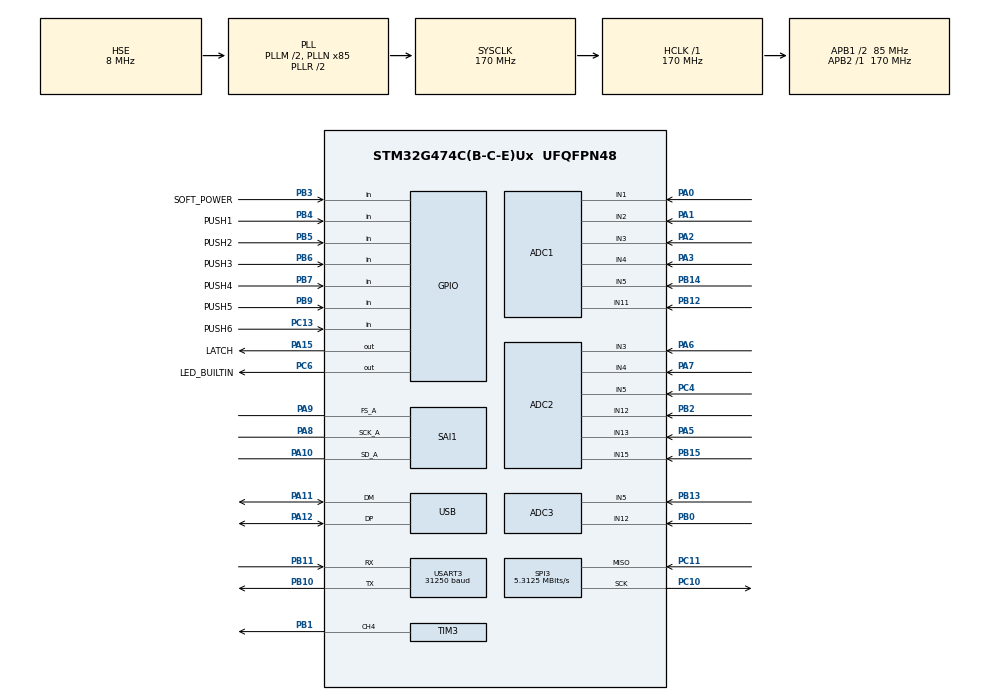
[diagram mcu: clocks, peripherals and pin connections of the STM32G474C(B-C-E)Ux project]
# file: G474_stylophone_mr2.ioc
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ADC1.Channel-0\#ChannelRegularConversion=ADC_CHANNEL_1
ADC1.Channel-1\#ChannelRegularConversion=ADC_CHANNEL_2
ADC1.Channel-2\#ChannelRegularConversion=ADC_CHANNEL_3
ADC1.Channel-3\#ChannelRegularConversion=ADC_CHANNEL_4
ADC1.Channel-4\#ChannelRegularConversion=ADC_CHANNEL_5
ADC1.Channel-5\#ChannelRegularConversion=ADC_CHANNEL_11
ADC1.DMAContinuousRequests=ENABLE
ADC1.EOCSelection=ADC_EOC_SEQ_CONV
ADC1.ExternalTrigConv=ADC_EXTERNALTRIG_T15_TRGO
ADC1.NbrOfConversion=6
ADC1.NbrOfConversionFlag=1
ADC1.OffsetNumber-0\#ChannelRegularConversion=ADC_OFFSET_NONE
ADC1.OffsetNumber-1\#ChannelRegularConversion=ADC_OFFSET_NONE
ADC1.OffsetNumber-2\#ChannelRegularConversion=ADC_OFFSET_NONE
ADC1.OffsetNumber-3\#ChannelRegularConversion=ADC_OFFSET_NONE
ADC1.OffsetNumber-4\#ChannelRegularConversion=ADC_OFFSET_NONE
ADC1.OffsetNumber-5\#ChannelRegularConversion=ADC_OFFSET_NONE
ADC1.Rank-0\#ChannelRegularConversion=1
ADC1.Rank-1\#ChannelRegularConversion=2
ADC1.Rank-2\#ChannelRegularConversion=3
ADC1.Rank-3\#ChannelRegularConversion=4
ADC1.Rank-4\#ChannelRegularConversion=5
ADC1.Rank-5\#ChannelRegularConversion=6
ADC1.SamplingTime-0\#ChannelRegularConversion=ADC_SAMPLETIME_2CYCLES_5
ADC1.SamplingTime-1\#ChannelRegularConversion=ADC_SAMPLETIME_2CYCLES_5
ADC1.SamplingTime-2\#ChannelRegularConversion=ADC_SAMPLETIME_2CYCLES_5
ADC1.SamplingTime-3\#ChannelRegularConversion=ADC_SAMPLETIME_2CYCLES_5
ADC1.SamplingTime-4\#ChannelRegularConversion=ADC_SAMPLETIME_2CYCLES_5
ADC1.SamplingTime-5\#ChannelRegularConversion=ADC_SAMPLETIME_2CYCLES_5
ADC1.master=1
ADC2.Channel-0\#ChannelRegularConversion=ADC_CHANNEL_3
ADC2.Channel-1\#ChannelRegularConversion=ADC_CHANNEL_4
ADC2.Channel-2\#ChannelRegularConversion=ADC_CHANNEL_5
ADC2.Channel-3\#ChannelRegularConversion=ADC_CHANNEL_12
ADC2.Channel-4\#ChannelRegularConversion=ADC_CHANNEL_13
ADC2.Channel-5\#ChannelRegularConversion=ADC_CHANNEL_15
ADC2.DMAContinuousRequests=ENABLE
ADC2.EOCSelection=ADC_EOC_SEQ_CONV
ADC2.ExternalTrigConv=ADC_EXTERNALTRIG_T15_TRGO
ADC2.NbrOfConversion=6
ADC2.NbrOfConversionFlag=1
ADC2.OffsetNumber-0\#ChannelRegularConversion=ADC_OFFSET_NONE
ADC2.OffsetNumber-1\#ChannelRegularConversion=ADC_OFFSET_NONE
ADC2.OffsetNumber-2\#ChannelRegularConversion=ADC_OFFSET_NONE
ADC2.OffsetNumber-3\#ChannelRegularConversion=ADC_OFFSET_NONE
ADC2.OffsetNumber-4\#ChannelRegularConversion=ADC_OFFSET_NONE
ADC2.OffsetNumber-5\#ChannelRegularConversion=ADC_OFFSET_NONE
ADC2.Rank-0\#ChannelRegularConversion=1
ADC2.Rank-1\#ChannelRegularConversion=2
ADC2.Rank-2\#ChannelRegularConversion=3
ADC2.Rank-3\#ChannelRegularConversion=4
ADC2.Rank-4\#ChannelRegularConversion=5
ADC2.Rank-5\#ChannelRegularConversion=6
ADC2.SamplingTime-0\#ChannelRegularConversion=ADC_SAMPLETIME_2CYCLES_5
ADC2.SamplingTime-1\#ChannelRegularConversion=ADC_SAMPLETIME_2CYCLES_5
ADC2.SamplingTime-2\#ChannelRegularConversion=ADC_SAMPLETIME_2CYCLES_5
ADC2.SamplingTime-3\#ChannelRegularConversion=ADC_SAMPLETIME_2CYCLES_5
ADC2.SamplingTime-4\#ChannelRegularConversion=ADC_SAMPLETIME_2CYCLES_5
ADC2.SamplingTime-5\#ChannelRegularConversion=ADC_SAMPLETIME_2CYCLES_5
ADC3.Channel-0\#ChannelRegularConversion=ADC_CHANNEL_5
ADC3.Channel-1\#ChannelRegularConversion=ADC_CHANNEL_12
ADC3.DMAContinuousRequests=ENABLE
ADC3.EOCSelection=ADC_EOC_SEQ_CONV
ADC3.ExternalTrigConv=ADC_EXTERNALTRIG_T15_TRGO
ADC3.NbrOfConversion=2
ADC3.NbrOfConversionFlag=1
ADC3.OffsetNumber-0\#ChannelRegularConversion=ADC_OFFSET_NONE
ADC3.OffsetNumber-1\#ChannelRegularConversion=ADC_OFFSET_NONE
ADC3.OversamplingMode=DISABLE
ADC3.Rank-0\#ChannelRegularConversion=1
ADC3.Rank-1\#ChannelRegularConversion=2
ADC3.SamplingTime-0\#ChannelRegularConversion=ADC_SAMPLETIME_2CYCLES_5
ADC3.SamplingTime-1\#ChannelRegularConversion=ADC_SAMPLETIME_2CYCLES_5
ADC3.master=1
Dma.ADC1.0.Direction=DMA_PERIPH_TO_MEMORY
Dma.ADC1.0.EventEnable=DISABLE
Dma.ADC1.0.Instance=DMA1_Channel1
Dma.ADC1.0.MemDataAlignment=DMA_MDATAALIGN_WORD
Dma.ADC1.0.MemInc=DMA_MINC_ENABLE
Dma.ADC1.0.Mode=DMA_CIRCULAR
Dma.ADC1.0.PeriphDataAlignment=DMA_PDATAALIGN_WORD
Dma.ADC1.0.PeriphInc=DMA_PINC_DISABLE
Dma.ADC1.0.Polarity=HAL_DMAMUX_REQ_GEN_RISING
Dma.ADC1.0.Priority=DMA_PRIORITY_LOW
Dma.ADC1.0.RequestNumber=1
Dma.ADC1.0.SignalID=NONE
Dma.ADC1.0.SyncEnable=DISABLE
Dma.ADC1.0.SyncPolarity=HAL_DMAMUX_SYNC_NO_EVENT
Dma.ADC1.0.SyncRequestNumber=1
Dma.ADC1.0.SyncSignalID=NONE
Dma.ADC2.1.Direction=DMA_PERIPH_TO_MEMORY
Dma.ADC2.1.EventEnable=DISABLE
Dma.ADC2.1.Instance=DMA1_Channel2
Dma.ADC2.1.MemDataAlignment=DMA_MDATAALIGN_WORD
Dma.ADC2.1.MemInc=DMA_MINC_ENABLE
Dma.ADC2.1.Mode=DMA_CIRCULAR
Dma.ADC2.1.PeriphDataAlignment=DMA_PDATAALIGN_WORD
Dma.ADC2.1.PeriphInc=DMA_PINC_DISABLE
Dma.ADC2.1.Polarity=HAL_DMAMUX_REQ_GEN_RISING
Dma.ADC2.1.Priority=DMA_PRIORITY_LOW
Dma.ADC2.1.RequestNumber=1
Dma.ADC2.1.SignalID=NONE
Dma.ADC2.1.SyncEnable=DISABLE
Dma.ADC2.1.SyncPolarity=HAL_DMAMUX_SYNC_NO_EVENT
Dma.ADC2.1.SyncRequestNumber=1
Dma.ADC2.1.SyncSignalID=NONE
Dma.ADC3.2.Direction=DMA_PERIPH_TO_MEMORY
Dma.ADC3.2.EventEnable=DISABLE
Dma.ADC3.2.Instance=DMA1_Channel3
Dma.ADC3.2.MemDataAlignment=DMA_MDATAALIGN_WORD
Dma.ADC3.2.MemInc=DMA_MINC_ENABLE
Dma.ADC3.2.Mode=DMA_CIRCULAR
Dma.ADC3.2.PeriphDataAlignment=DMA_PDATAALIGN_WORD
Dma.ADC3.2.PeriphInc=DMA_PINC_DISABLE
Dma.ADC3.2.Polarity=HAL_DMAMUX_REQ_GEN_RISING
Dma.ADC3.2.Priority=DMA_PRIORITY_LOW
Dma.ADC3.2.RequestNumber=1
Dma.ADC3.2.SignalID=NONE
Dma.ADC3.2.SyncEnable=DISABLE
Dma.ADC3.2.SyncPolarity=HAL_DMAMUX_SYNC_NO_EVENT
Dma.ADC3.2.SyncRequestNumber=1
Dma.ADC3.2.SyncSignalID=NONE
Dma.Request0=ADC1
Dma.Request1=ADC2
Dma.Request2=ADC3
Dma.Request3=SAI1_A
Dma.Request4=SPI3_RX
Dma.Request5=TIM3_CH4
Dma.SAI1_A.3.Direction=DMA_MEMORY_TO_PERIPH
Dma.SAI1_A.3.EventEnable=DISABLE
Dma.SAI1_A.3.Instance=DMA1_Channel4
Dma.SAI1_A.3.MemDataAlignment=DMA_MDATAALIGN_WORD
Dma.SAI1_A.3.MemInc=DMA_MINC_ENABLE
Dma.SAI1_A.3.Mode=DMA_CIRCULAR
Dma.SAI1_A.3.PeriphDataAlignment=DMA_PDATAALIGN_WORD
Dma.SAI1_A.3.PeriphInc=DMA_PINC_DISABLE
Dma.SAI1_A.3.Polarity=HAL_DMAMUX_REQ_GEN_RISING
Dma.SAI1_A.3.Priority=DMA_PRIORITY_HIGH
Dma.SAI1_A.3.RequestNumber=1
Dma.SAI1_A.3.SignalID=NONE
Dma.SAI1_A.3.SyncEnable=DISABLE
Dma.SAI1_A.3.SyncPolarity=HAL_DMAMUX_SYNC_NO_EVENT
Dma.SAI1_A.3.SyncRequestNumber=1
Dma.SAI1_A.3.SyncSignalID=NONE
Dma.SPI3_RX.4.Direction=DMA_PERIPH_TO_MEMORY
Dma.SPI3_RX.4.EventEnable=DISABLE
Dma.SPI3_RX.4.Instance=DMA1_Channel5
Dma.SPI3_RX.4.MemDataAlignment=DMA_MDATAALIGN_BYTE
Dma.SPI3_RX.4.MemInc=DMA_MINC_ENABLE
Dma.SPI3_RX.4.Mode=DMA_NORMAL
Dma.SPI3_RX.4.PeriphDataAlignment=DMA_PDATAALIGN_BYTE
Dma.SPI3_RX.4.PeriphInc=DMA_PINC_DISABLE
Dma.SPI3_RX.4.Polarity=HAL_DMAMUX_REQ_GEN_RISING
Dma.SPI3_RX.4.Priority=DMA_PRIORITY_LOW
Dma.SPI3_RX.4.RequestNumber=1
Dma.SPI3_RX.4.SignalID=NONE
Dma.SPI3_RX.4.SyncEnable=DISABLE
Dma.SPI3_RX.4.SyncPolarity=HAL_DMAMUX_SYNC_NO_EVENT
Dma.SPI3_RX.4.SyncRequestNumber=1
Dma.SPI3_RX.4.SyncSignalID=NONE
Dma.TIM3_CH4.5.Direction=DMA_MEMORY_TO_PERIPH
Dma.TIM3_CH4.5.EventEnable=DISABLE
Dma.TIM3_CH4.5.Instance=DMA1_Channel6
Dma.TIM3_CH4.5.MemDataAlignment=DMA_MDATAALIGN_BYTE
Dma.TIM3_CH4.5.MemInc=DMA_MINC_ENABLE
Dma.TIM3_CH4.5.Mode=DMA_NORMAL
Dma.TIM3_CH4.5.PeriphDataAlignment=DMA_PDATAALIGN_WORD
Dma.TIM3_CH4.5.PeriphInc=DMA_PINC_DISABLE
Dma.TIM3_CH4.5.Polarity=HAL_DMAMUX_REQ_GEN_RISING
Dma.TIM3_CH4.5.Priority=DMA_PRIORITY_LOW
Dma.TIM3_CH4.5.RequestNumber=1
Dma.TIM3_CH4.5.SignalID=NONE
Dma.TIM3_CH4.5.SyncEnable=DISABLE
Dma.TIM3_CH4.5.SyncPolarity=HAL_DMAMUX_SYNC_NO_EVENT
Dma.TIM3_CH4.5.SyncRequestNumber=1
Dma.TIM3_CH4.5.SyncSignalID=NONE
Mcu.Family=STM32G4
Mcu.Name=STM32G474C(B-C-E)Ux
Mcu.Package=UFQFPN48
NVIC.DMA1_Channel1_IRQn=true\:0\:0\:false\:false\:true\:false\:true\:true
NVIC.DMA1_Channel2_IRQn=true\:0\:0\:false\:false\:true\:false\:true\:true
NVIC.DMA1_Channel3_IRQn=true\:0\:0\:false\:false\:true\:false\:true\:true
NVIC.DMA1_Channel4_IRQn=true\:10\:0\:true\:false\:true\:false\:true\:true
NVIC.DMA1_Channel5_IRQn=true\:0\:0\:false\:false\:true\:false\:true\:true
NVIC.DMA1_Channel6_IRQn=true\:0\:0\:false\:false\:true\:false\:true\:true
NVIC.PriorityGroup=NVIC_PRIORITYGROUP_4
NVIC.USB_LP_IRQn=true\:0\:0\:false\:false\:true\:false\:true\:true
PA0.Mode=IN1-Single-Ended
PA0.Signal=ADC1_IN1
PA1.Mode=IN2-Single-Ended
PA1.Signal=ADC1_IN2
PA10.Mode=SAI_A_Master
PA10.Signal=SAI1_SD_A
PA11.Mode=Device
PA11.Signal=USB_DM
PA12.Mode=Device
PA12.Signal=USB_DP
PA13.Mode=Serial_Wire
PA13.Signal=SYS_JTMS-SWDIO
PA14.Mode=Serial_Wire
PA14.Signal=SYS_JTCK-SWCLK
PA15.GPIO_Label=LATCH
PA15.Signal=GPIO_Output
PA2.Mode=IN3-Single-Ended
PA2.Signal=ADC1_IN3
PA3.Mode=IN4-Single-Ended
PA3.Signal=ADC1_IN4
PA5.Mode=IN13-Single-Ended
PA5.Signal=ADC2_IN13
PA6.Mode=IN3-Single-Ended
PA6.Signal=ADC2_IN3
PA7.Mode=IN4-Single-Ended
PA7.Signal=ADC2_IN4
PA8.Mode=SAI_A_Master
PA8.Signal=SAI1_SCK_A
PA9.Mode=SAI_A_Master
PA9.Signal=SAI1_FS_A
PB0.Mode=IN12-Single-Ended
PB0.Signal=ADC3_IN12
PB1.Signal=S_TIM3_CH4
PB10.Mode=Asynchronous
PB10.Signal=USART3_TX
PB11.Mode=Asynchronous
PB11.Signal=USART3_RX
PB12.Mode=IN11-Single-Ended
PB12.Signal=ADC1_IN11
PB13.Mode=IN5-Single-Ended
PB13.Signal=ADC3_IN5
PB14.Mode=IN5-Single-Ended
PB14.Signal=ADC1_IN5
PB15.Mode=IN15-Single-Ended
PB15.Signal=ADC2_IN15
PB2.Mode=IN12-Single-Ended
PB2.Signal=ADC2_IN12
PB3.GPIO_Label=SOFT_POWER
PB3.GPIO_Mode=GPIO_MODE_INPUT
PB3.GPIO_PuPd=GPIO_PULLUP
PB3.Signal=GPIO_Input
PB4.GPIO_Label=PUSH1
PB4.GPIO_Mode=GPIO_MODE_INPUT
PB4.GPIO_PuPd=GPIO_PULLUP
PB4.Signal=GPIO_Input
PB5.GPIO_Label=PUSH2
PB5.GPIO_Mode=GPIO_MODE_INPUT
PB5.GPIO_PuPd=GPIO_PULLUP
PB5.Signal=GPIO_Input
PB6.GPIO_Label=PUSH3
PB6.GPIO_Mode=GPIO_MODE_INPUT
PB6.GPIO_PuPd=GPIO_PULLUP
PB6.Signal=GPIO_Input
PB7.GPIO_Label=PUSH4
PB7.GPIO_Mode=GPIO_MODE_INPUT
PB7.GPIO_PuPd=GPIO_PULLUP
PB7.Signal=GPIO_Input
PB9.GPIO_Label=PUSH5
PB9.GPIO_PuPd=GPIO_PULLUP
PB9.Signal=GPIO_Input
PC10.Mode=RX_Only_Simplex_Unidirect_Master
PC10.Signal=SPI3_SCK
PC11.Mode=RX_Only_Simplex_Unidirect_Master
PC11.Signal=SPI3_MISO
PC13.GPIO_Label=PUSH6
PC13.GPIO_PuPd=GPIO_PULLUP
PC13.Signal=GPIO_Input
PC14-OSC32_IN.Mode=LSE-External-Oscillator
PC14-OSC32_IN.Signal=RCC_OSC32_IN
PC15-OSC32_OUT.Mode=LSE-External-Oscillator
PC15-OSC32_OUT.Signal=RCC_OSC32_OUT
PC4.Mode=IN5-Single-Ended
PC4.Signal=ADC2_IN5
PC6.GPIO_Label=LED_BUILTIN
PC6.Signal=GPIO_Output
PF0-OSC_IN.Mode=HSE-External-Oscillator
PF0-OSC_IN.Signal=RCC_OSC_IN
PF1-OSC_OUT.Mode=HSE-External-Oscillator
PF1-OSC_OUT.Signal=RCC_OSC_OUT
ProjectManager.HeapSize=0x200
ProjectManager.StackSize=0x400
ProjectManager.TargetToolchain=STM32CubeIDE
RCC.ADC12Freq_Value=170000000
RCC.ADC345Freq_Value=170000000
RCC.AHBFreq_Value=170000000
RCC.APB1CLKDivider=RCC_HCLK_DIV2
RCC.APB1Freq_Value=85000000
RCC.APB1TimFreq_Value=170000000
RCC.APB2Freq_Value=170000000
RCC.APB2TimFreq_Value=170000000
RCC.CK48CLockSelection=RCC_USBCLKSOURCE_HSI48
RCC.CortexFreq_Value=170000000
RCC.EXTERNAL_CLOCK_VALUE=12288000
RCC.HCLKFreq_Value=170000000
RCC.HSE_VALUE=8000000
RCC.HSI48_VALUE=48000000
RCC.HSI_VALUE=16000000
RCC.PLLM=RCC_PLLM_DIV2
RCC.PLLN=85
RCC.PLLSourceVirtual=RCC_PLLSOURCE_HSE
RCC.RTCClockSelection=RCC_RTCCLKSOURCE_LSE
RCC.SAI1CLockSelection=RCC_SAI1CLKSOURCE_PLL
RCC.SYSCLKFreq_VALUE=170000000
RCC.SYSCLKSource=RCC_SYSCLKSOURCE_PLLCLK
RCC.USBFreq_Value=48000000
RCC.VCOOutputFreq_Value=340000000
SAI1.AudioFrequency-SAI_A_Master=SAI_AUDIO_FREQUENCY_44K
SAI1.BasicDataSize-SAI_A_Master=SAI_PROTOCOL_DATASIZE_32BIT
SAI1.InitProtocol-SAI_A_Master=Enable
SAI1.Instance-SAI_A_Master=SAI$Index_Block_A
SAI1.MckOutput-SAI_A_Master=SAI_MCK_OUTPUT_DISABLE
SAI1.VirtualMode-SAI_A_Master=VM_MASTER
SAI1.VirtualProtocol-SAI_A_BASIC=VM_BASIC_PROTOCOL
SH.S_TIM3_CH4.0=TIM3_CH4,PWM Generation4 CH4
SPI3.BaudRatePrescaler=SPI_BAUDRATEPRESCALER_16
SPI3.CalculateBaudRate=5.3125 MBits/s
SPI3.DataSize=SPI_DATASIZE_8BIT
SPI3.Direction=SPI_DIRECTION_2LINES_RXONLY
SPI3.FirstBit=SPI_FIRSTBIT_LSB
SPI3.Mode=SPI_MODE_MASTER
SPI3.NSSPMode=SPI_NSS_PULSE_DISABLE
SPI3.VirtualType=VM_MASTER
TIM15.AutoReloadPreload=TIM_AUTORELOAD_PRELOAD_ENABLE
TIM15.PeriodNoDither=170-1
TIM15.Prescaler=1000-1
TIM15.TIM_MasterOutputTrigger=TIM_TRGO_UPDATE
TIM3.AutoReloadPreload=TIM_AUTORELOAD_PRELOAD_ENABLE
TIM3.Channel-PWM\ Generation4\ CH4=TIM_CHANNEL_4
TIM3.PeriodNoDither=200
TIM5.AutoReloadPreload=TIM_AUTORELOAD_PRELOAD_ENABLE
TIM5.Prescaler=170-1
USART3.BaudRate=31250
USART3.VirtualMode-Asynchronous=VM_ASYNC
USB_DEVICE.CLASS_NAME_FS=CDC
USB_DEVICE.LANGID_STRING=1031
USB_DEVICE.VirtualMode=Cdc
USB_DEVICE.VirtualModeFS=Cdc_FS
VP_CORDIC_VS_CORDIC.Mode=CORDIC_Activate
VP_FMAC_VS_FMAC.Mode=FMAC_Activate
VP_RTC_VS_RTC_Activate.Mode=RTC_Enabled
VP_SAI1_VP_$IpInstance_SAIA_SAI_BASIC.Mode=SAI_A_BASIC
VP_SYS_VS_DBSignals.Mode=DisableDeadBatterySignals
VP_TIM15_VS_ClockSourceINT.Mode=Internal
VP_TIM3_VS_ClockSourceINT.Mode=Internal
VP_TIM5_VS_ClockSourceINT.Mode=Internal
VP_USB_DEVICE_VS_USB_DEVICE_CDC_FS.Mode=CDC_FS
board=custom

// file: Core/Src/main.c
/* USER CODE BEGIN Header */
/**
 ******************************************************************************
 * @file           : main.c
 * @brief          : Main program body
 ******************************************************************************
 * @attention
 *
 * Copyright (c) 2025 STMicroelectronics.
 * All rights reserved.
 *
 * This software is licensed under terms that can be found in the LICENSE file
 * in the root directory of this software component.
 * If no LICENSE file comes with this software, it is provided AS-IS.
 *
 ******************************************************************************
 */
/* USER CODE END Header */
#include "main.h"
#include "usb_device.h"

/* USER CODE BEGIN Includes */
#include "app.h"

/* USER CODE END Includes */

ADC_HandleTypeDef hadc1;
ADC_HandleTypeDef hadc2;
ADC_HandleTypeDef hadc3;
DMA_HandleTypeDef hdma_adc1;
DMA_HandleTypeDef hdma_adc2;
DMA_HandleTypeDef hdma_adc3;

CORDIC_HandleTypeDef hcordic;

FMAC_HandleTypeDef hfmac;

RTC_HandleTypeDef hrtc;

SAI_HandleTypeDef hsai_BlockA1;
DMA_HandleTypeDef hdma_sai1_a;

SPI_HandleTypeDef hspi3;
DMA_HandleTypeDef hdma_spi3_rx;

TIM_HandleTypeDef htim3;
TIM_HandleTypeDef htim5;
TIM_HandleTypeDef htim15;
DMA_HandleTypeDef hdma_tim3_ch4;

UART_HandleTypeDef huart3;

void SystemClock_Config(void);
static void MX_GPIO_Init(void);
static void MX_DMA_Init(void);
static void MX_ADC1_Init(void);
static void MX_CORDIC_Init(void);
static void MX_FMAC_Init(void);
static void MX_ADC2_Init(void);
static void MX_ADC3_Init(void);
static void MX_TIM15_Init(void);
static void MX_TIM5_Init(void);
static void MX_SAI1_Init(void);
static void MX_SPI3_Init(void);
static void MX_TIM3_Init(void);
static void MX_RTC_Init(void);
static void MX_USART3_UART_Init(void);

int main(void)
{

  /* MCU Configuration--------------------------------------------------------*/

  /* Reset of all peripherals, Initializes the Flash interface and the Systick. */
  HAL_Init();

  /* Configure the system clock */
  SystemClock_Config();

  /* Initialize all configured peripherals */
  MX_GPIO_Init();
  MX_DMA_Init();
  MX_ADC1_Init();
  MX_CORDIC_Init();
  MX_FMAC_Init();
  MX_USB_Device_Init();
  MX_ADC2_Init();
  MX_ADC3_Init();
  MX_TIM15_Init();
  MX_TIM5_Init();
  MX_SAI1_Init();
  MX_SPI3_Init();
  MX_TIM3_Init();
  MX_RTC_Init();
  MX_USART3_UART_Init();

  /* Infinite loop */
  /* USER CODE BEGIN WHILE */
	setup();
	while (1) {
		loop();
    /* USER CODE END WHILE */

	}
}

void SystemClock_Config(void)
{
  RCC_OscInitTypeDef RCC_OscInitStruct = {0};
  RCC_ClkInitTypeDef RCC_ClkInitStruct = {0};

  /** Configure the main internal regulator output voltage
  */
  HAL_PWREx_ControlVoltageScaling(PWR_REGULATOR_VOLTAGE_SCALE1_BOOST);

  /** Configure LSE Drive Capability
  */
  HAL_PWR_EnableBkUpAccess();
  __HAL_RCC_LSEDRIVE_CONFIG(RCC_LSEDRIVE_LOW);

  /** Initializes the RCC Oscillators according to the specified parameters
  * in the RCC_OscInitTypeDef structure.
  */
  RCC_OscInitStruct.OscillatorType = RCC_OSCILLATORTYPE_HSI48|RCC_OSCILLATORTYPE_HSE
                              |RCC_OSCILLATORTYPE_LSE;
  RCC_OscInitStruct.HSEState = RCC_HSE_ON;
  RCC_OscInitStruct.LSEState = RCC_LSE_ON;
  RCC_OscInitStruct.HSI48State = RCC_HSI48_ON;
  RCC_OscInitStruct.PLL.PLLState = RCC_PLL_ON;
  RCC_OscInitStruct.PLL.PLLSource = RCC_PLLSOURCE_HSE;
  RCC_OscInitStruct.PLL.PLLM = RCC_PLLM_DIV2;
  RCC_OscInitStruct.PLL.PLLN = 85;
  RCC_OscInitStruct.PLL.PLLP = RCC_PLLP_DIV2;
  RCC_OscInitStruct.PLL.PLLQ = RCC_PLLQ_DIV2;
  RCC_OscInitStruct.PLL.PLLR = RCC_PLLR_DIV2;
  if (HAL_RCC_OscConfig(&RCC_OscInitStruct) != HAL_OK)
  {
    Error_Handler();
  }

  /** Initializes the CPU, AHB and APB buses clocks
  */
  RCC_ClkInitStruct.ClockType = RCC_CLOCKTYPE_HCLK|RCC_CLOCKTYPE_SYSCLK
                              |RCC_CLOCKTYPE_PCLK1|RCC_CLOCKTYPE_PCLK2;
  RCC_ClkInitStruct.SYSCLKSource = RCC_SYSCLKSOURCE_PLLCLK;
  RCC_ClkInitStruct.AHBCLKDivider = RCC_SYSCLK_DIV1;
  RCC_ClkInitStruct.APB1CLKDivider = RCC_HCLK_DIV2;
  RCC_ClkInitStruct.APB2CLKDivider = RCC_HCLK_DIV1;

  if (HAL_RCC_ClockConfig(&RCC_ClkInitStruct, FLASH_LATENCY_4) != HAL_OK)
  {
    Error_Handler();
  }
}

static void MX_ADC1_Init(void)
{

  ADC_MultiModeTypeDef multimode = {0};
  ADC_ChannelConfTypeDef sConfig = {0};

  /** Common config
  */
  hadc1.Instance = ADC1;
  hadc1.Init.ClockPrescaler = ADC_CLOCK_SYNC_PCLK_DIV4;
  hadc1.Init.Resolution = ADC_RESOLUTION_12B;
  hadc1.Init.DataAlign = ADC_DATAALIGN_RIGHT;
  hadc1.Init.GainCompensation = 0;
  hadc1.Init.ScanConvMode = ADC_SCAN_ENABLE;
  hadc1.Init.EOCSelection = ADC_EOC_SEQ_CONV;
  hadc1.Init.LowPowerAutoWait = DISABLE;
  hadc1.Init.ContinuousConvMode = DISABLE;
  hadc1.Init.NbrOfConversion = 6;
  hadc1.Init.DiscontinuousConvMode = DISABLE;
  hadc1.Init.ExternalTrigConv = ADC_EXTERNALTRIG_T15_TRGO;
  hadc1.Init.ExternalTrigConvEdge = ADC_EXTERNALTRIGCONVEDGE_RISING;
  hadc1.Init.DMAContinuousRequests = ENABLE;
  hadc1.Init.Overrun = ADC_OVR_DATA_PRESERVED;
  hadc1.Init.OversamplingMode = DISABLE;
  if (HAL_ADC_Init(&hadc1) != HAL_OK)
  {
    Error_Handler();
  }

  /** Configure the ADC multi-mode
  */
  multimode.Mode = ADC_MODE_INDEPENDENT;
  if (HAL_ADCEx_MultiModeConfigChannel(&hadc1, &multimode) != HAL_OK)
  {
    Error_Handler();
  }

  /** Configure Regular Channel
  */
  sConfig.Channel = ADC_CHANNEL_1;
  sConfig.Rank = ADC_REGULAR_RANK_1;
  sConfig.SamplingTime = ADC_SAMPLETIME_2CYCLES_5;
  sConfig.SingleDiff = ADC_SINGLE_ENDED;
  sConfig.OffsetNumber = ADC_OFFSET_NONE;
  sConfig.Offset = 0;
  if (HAL_ADC_ConfigChannel(&hadc1, &sConfig) != HAL_OK)
  {
    Error_Handler();
  }

  /** Configure Regular Channel
  */
  sConfig.Channel = ADC_CHANNEL_2;
  sConfig.Rank = ADC_REGULAR_RANK_2;
  if (HAL_ADC_ConfigChannel(&hadc1, &sConfig) != HAL_OK)
  {
    Error_Handler();
  }

  /** Configure Regular Channel
  */
  sConfig.Channel = ADC_CHANNEL_3;
  sConfig.Rank = ADC_REGULAR_RANK_3;
  if (HAL_ADC_ConfigChannel(&hadc1, &sConfig) != HAL_OK)
  {
    Error_Handler();
  }

  /** Configure Regular Channel
  */
  sConfig.Channel = ADC_CHANNEL_4;
  sConfig.Rank = ADC_REGULAR_RANK_4;
  if (HAL_ADC_ConfigChannel(&hadc1, &sConfig) != HAL_OK)
  {
    Error_Handler();
  }

  /** Configure Regular Channel
  */
  sConfig.Channel = ADC_CHANNEL_5;
  sConfig.Rank = ADC_REGULAR_RANK_5;
  if (HAL_ADC_ConfigChannel(&hadc1, &sConfig) != HAL_OK)
  {
    Error_Handler();
  }

  /** Configure Regular Channel
  */
  sConfig.Channel = ADC_CHANNEL_11;
  sConfig.Rank = ADC_REGULAR_RANK_6;
  if (HAL_ADC_ConfigChannel(&hadc1, &sConfig) != HAL_OK)
  {
    Error_Handler();
  }

}

static void MX_ADC2_Init(void)
{

  ADC_ChannelConfTypeDef sConfig = {0};

  /** Common config
  */
  hadc2.Instance = ADC2;
  hadc2.Init.ClockPrescaler = ADC_CLOCK_SYNC_PCLK_DIV4;
  hadc2.Init.Resolution = ADC_RESOLUTION_12B;
  hadc2.Init.DataAlign = ADC_DATAALIGN_RIGHT;
  hadc2.Init.GainCompensation = 0;
  hadc2.Init.ScanConvMode = ADC_SCAN_ENABLE;
  hadc2.Init.EOCSelection = ADC_EOC_SEQ_CONV;
  hadc2.Init.LowPowerAutoWait = DISABLE;
  hadc2.Init.ContinuousConvMode = DISABLE;
  hadc2.Init.NbrOfConversion = 6;
  hadc2.Init.DiscontinuousConvMode = DISABLE;
  hadc2.Init.ExternalTrigConv = ADC_EXTERNALTRIG_T15_TRGO;
  hadc2.Init.ExternalTrigConvEdge = ADC_EXTERNALTRIGCONVEDGE_RISING;
  hadc2.Init.DMAContinuousRequests = ENABLE;
  hadc2.Init.Overrun = ADC_OVR_DATA_PRESERVED;
  hadc2.Init.OversamplingMode = DISABLE;
  if (HAL_ADC_Init(&hadc2) != HAL_OK)
  {
    Error_Handler();
  }

  /** Configure Regular Channel
  */
  sConfig.Channel = ADC_CHANNEL_3;
  sConfig.Rank = ADC_REGULAR_RANK_1;
  sConfig.SamplingTime = ADC_SAMPLETIME_2CYCLES_5;
  sConfig.SingleDiff = ADC_SINGLE_ENDED;
  sConfig.OffsetNumber = ADC_OFFSET_NONE;
  sConfig.Offset = 0;
  if (HAL_ADC_ConfigChannel(&hadc2, &sConfig) != HAL_OK)
  {
    Error_Handler();
  }

  /** Configure Regular Channel
  */
  sConfig.Channel = ADC_CHANNEL_4;
  sConfig.Rank = ADC_REGULAR_RANK_2;
  if (HAL_ADC_ConfigChannel(&hadc2, &sConfig) != HAL_OK)
  {
    Error_Handler();
  }

  /** Configure Regular Channel
  */
  sConfig.Channel = ADC_CHANNEL_5;
  sConfig.Rank = ADC_REGULAR_RANK_3;
  if (HAL_ADC_ConfigChannel(&hadc2, &sConfig) != HAL_OK)
  {
    Error_Handler();
  }

  /** Configure Regular Channel
  */
  sConfig.Channel = ADC_CHANNEL_12;
  sConfig.Rank = ADC_REGULAR_RANK_4;
  if (HAL_ADC_ConfigChannel(&hadc2, &sConfig) != HAL_OK)
  {
    Error_Handler();
  }

  /** Configure Regular Channel
  */
  sConfig.Channel = ADC_CHANNEL_13;
  sConfig.Rank = ADC_REGULAR_RANK_5;
  if (HAL_ADC_ConfigChannel(&hadc2, &sConfig) != HAL_OK)
  {
    Error_Handler();
  }

  /** Configure Regular Channel
  */
  sConfig.Channel = ADC_CHANNEL_15;
  sConfig.Rank = ADC_REGULAR_RANK_6;
  if (HAL_ADC_ConfigChannel(&hadc2, &sConfig) != HAL_OK)
  {
    Error_Handler();
  }

}

static void MX_ADC3_Init(void)
{

  ADC_MultiModeTypeDef multimode = {0};
  ADC_ChannelConfTypeDef sConfig = {0};

  /** Common config
  */
  hadc3.Instance = ADC3;
  hadc3.Init.ClockPrescaler = ADC_CLOCK_SYNC_PCLK_DIV4;
  hadc3.Init.Resolution = ADC_RESOLUTION_12B;
  hadc3.Init.DataAlign = ADC_DATAALIGN_RIGHT;
  hadc3.Init.GainCompensation = 0;
  hadc3.Init.ScanConvMode = ADC_SCAN_ENABLE;
  hadc3.Init.EOCSelection = ADC_EOC_SEQ_CONV;
  hadc3.Init.LowPowerAutoWait = DISABLE;
  hadc3.Init.ContinuousConvMode = DISABLE;
  hadc3.Init.NbrOfConversion = 2;
  hadc3.Init.DiscontinuousConvMode = DISABLE;
  hadc3.Init.ExternalTrigConv = ADC_EXTERNALTRIG_T15_TRGO;
  hadc3.Init.ExternalTrigConvEdge = ADC_EXTERNALTRIGCONVEDGE_RISING;
  hadc3.Init.DMAContinuousRequests = ENABLE;
  hadc3.Init.Overrun = ADC_OVR_DATA_PRESERVED;
  hadc3.Init.OversamplingMode = DISABLE;
  if (HAL_ADC_Init(&hadc3) != HAL_OK)
  {
    Error_Handler();
  }

  /** Configure the ADC multi-mode
  */
  multimode.Mode = ADC_MODE_INDEPENDENT;
  if (HAL_ADCEx_MultiModeConfigChannel(&hadc3, &multimode) != HAL_OK)
  {
    Error_Handler();
  }

  /** Configure Regular Channel
  */
  sConfig.Channel = ADC_CHANNEL_5;
  sConfig.Rank = ADC_REGULAR_RANK_1;
  sConfig.SamplingTime = ADC_SAMPLETIME_2CYCLES_5;
  sConfig.SingleDiff = ADC_SINGLE_ENDED;
  sConfig.OffsetNumber = ADC_OFFSET_NONE;
  sConfig.Offset = 0;
  if (HAL_ADC_ConfigChannel(&hadc3, &sConfig) != HAL_OK)
  {
    Error_Handler();
  }

  /** Configure Regular Channel
  */
  sConfig.Channel = ADC_CHANNEL_12;
  sConfig.Rank = ADC_REGULAR_RANK_2;
  if (HAL_ADC_ConfigChannel(&hadc3, &sConfig) != HAL_OK)
  {
    Error_Handler();
  }

}

static void MX_CORDIC_Init(void)
{

  hcordic.Instance = CORDIC;
  if (HAL_CORDIC_Init(&hcordic) != HAL_OK)
  {
    Error_Handler();
  }

}

static void MX_FMAC_Init(void)
{

  hfmac.Instance = FMAC;
  if (HAL_FMAC_Init(&hfmac) != HAL_OK)
  {
    Error_Handler();
  }

}

static void MX_RTC_Init(void)
{

  /** Initialize RTC Only
  */
  hrtc.Instance = RTC;
  hrtc.Init.HourFormat = RTC_HOURFORMAT_24;
  hrtc.Init.AsynchPrediv = 127;
  hrtc.Init.SynchPrediv = 255;
  hrtc.Init.OutPut = RTC_OUTPUT_DISABLE;
  hrtc.Init.OutPutRemap = RTC_OUTPUT_REMAP_NONE;
  hrtc.Init.OutPutPolarity = RTC_OUTPUT_POLARITY_HIGH;
  hrtc.Init.OutPutType = RTC_OUTPUT_TYPE_OPENDRAIN;
  hrtc.Init.OutPutPullUp = RTC_OUTPUT_PULLUP_NONE;
  if (HAL_RTC_Init(&hrtc) != HAL_OK)
  {
    Error_Handler();
  }

}

static void MX_SAI1_Init(void)
{

  hsai_BlockA1.Instance = SAI1_Block_A;
  hsai_BlockA1.Init.AudioMode = SAI_MODEMASTER_TX;
  hsai_BlockA1.Init.Synchro = SAI_ASYNCHRONOUS;
  hsai_BlockA1.Init.OutputDrive = SAI_OUTPUTDRIVE_DISABLE;
  hsai_BlockA1.Init.NoDivider = SAI_MASTERDIVIDER_ENABLE;
  hsai_BlockA1.Init.MckOverSampling = SAI_MCK_OVERSAMPLING_DISABLE;
  hsai_BlockA1.Init.FIFOThreshold = SAI_FIFOTHRESHOLD_EMPTY;
  hsai_BlockA1.Init.AudioFrequency = SAI_AUDIO_FREQUENCY_44K;
  hsai_BlockA1.Init.SynchroExt = SAI_SYNCEXT_DISABLE;
  hsai_BlockA1.Init.MonoStereoMode = SAI_STEREOMODE;
  hsai_BlockA1.Init.CompandingMode = SAI_NOCOMPANDING;
  hsai_BlockA1.Init.TriState = SAI_OUTPUT_NOTRELEASED;
  if (HAL_SAI_InitProtocol(&hsai_BlockA1, SAI_I2S_STANDARD, SAI_PROTOCOL_DATASIZE_32BIT, 2) != HAL_OK)
  {
    Error_Handler();
  }

}

static void MX_SPI3_Init(void)
{

  /* SPI3 parameter configuration*/
  hspi3.Instance = SPI3;
  hspi3.Init.Mode = SPI_MODE_MASTER;
  hspi3.Init.Direction = SPI_DIRECTION_2LINES_RXONLY;
  hspi3.Init.DataSize = SPI_DATASIZE_8BIT;
  hspi3.Init.CLKPolarity = SPI_POLARITY_LOW;
  hspi3.Init.CLKPhase = SPI_PHASE_1EDGE;
  hspi3.Init.NSS = SPI_NSS_SOFT;
  hspi3.Init.BaudRatePrescaler = SPI_BAUDRATEPRESCALER_16;
  hspi3.Init.FirstBit = SPI_FIRSTBIT_LSB;
  hspi3.Init.TIMode = SPI_TIMODE_DISABLE;
  hspi3.Init.CRCCalculation = SPI_CRCCALCULATION_DISABLE;
  hspi3.Init.CRCPolynomial = 7;
  hspi3.Init.CRCLength = SPI_CRC_LENGTH_DATASIZE;
  hspi3.Init.NSSPMode = SPI_NSS_PULSE_DISABLE;
  if (HAL_SPI_Init(&hspi3) != HAL_OK)
  {
    Error_Handler();
  }

}

static void MX_TIM3_Init(void)
{

  TIM_ClockConfigTypeDef sClockSourceConfig = {0};
  TIM_MasterConfigTypeDef sMasterConfig = {0};
  TIM_OC_InitTypeDef sConfigOC = {0};

  htim3.Instance = TIM3;
  htim3.Init.Prescaler = 0;
  htim3.Init.CounterMode = TIM_COUNTERMODE_UP;
  htim3.Init.Period = 200;
  htim3.Init.ClockDivision = TIM_CLOCKDIVISION_DIV1;
  htim3.Init.AutoReloadPreload = TIM_AUTORELOAD_PRELOAD_ENABLE;
  if (HAL_TIM_Base_Init(&htim3) != HAL_OK)
  {
    Error_Handler();
  }
  sClockSourceConfig.ClockSource = TIM_CLOCKSOURCE_INTERNAL;
  if (HAL_TIM_ConfigClockSource(&htim3, &sClockSourceConfig) != HAL_OK)
  {
    Error_Handler();
  }
  if (HAL_TIM_PWM_Init(&htim3) != HAL_OK)
  {
    Error_Handler();
  }
  sMasterConfig.MasterOutputTrigger = TIM_TRGO_RESET;
  sMasterConfig.MasterSlaveMode = TIM_MASTERSLAVEMODE_DISABLE;
  if (HAL_TIMEx_MasterConfigSynchronization(&htim3, &sMasterConfig) != HAL_OK)
  {
    Error_Handler();
  }
  sConfigOC.OCMode = TIM_OCMODE_PWM1;
  sConfigOC.Pulse = 0;
  sConfigOC.OCPolarity = TIM_OCPOLARITY_HIGH;
  sConfigOC.OCFastMode = TIM_OCFAST_DISABLE;
  if (HAL_TIM_PWM_ConfigChannel(&htim3, &sConfigOC, TIM_CHANNEL_4) != HAL_OK)
  {
    Error_Handler();
  }
  HAL_TIM_MspPostInit(&htim3);

}

static void MX_TIM5_Init(void)
{

  TIM_ClockConfigTypeDef sClockSourceConfig = {0};
  TIM_MasterConfigTypeDef sMasterConfig = {0};

  htim5.Instance = TIM5;
  htim5.Init.Prescaler = 170-1;
  htim5.Init.CounterMode = TIM_COUNTERMODE_UP;
  htim5.Init.Period = 4294967295;
  htim5.Init.ClockDivision = TIM_CLOCKDIVISION_DIV1;
  htim5.Init.AutoReloadPreload = TIM_AUTORELOAD_PRELOAD_ENABLE;
  if (HAL_TIM_Base_Init(&htim5) != HAL_OK)
  {
    Error_Handler();
  }
  sClockSourceConfig.ClockSource = TIM_CLOCKSOURCE_INTERNAL;
  if (HAL_TIM_ConfigClockSource(&htim5, &sClockSourceConfig) != HAL_OK)
  {
    Error_Handler();
  }
  sMasterConfig.MasterOutputTrigger = TIM_TRGO_RESET;
  sMasterConfig.MasterSlaveMode = TIM_MASTERSLAVEMODE_DISABLE;
  if (HAL_TIMEx_MasterConfigSynchronization(&htim5, &sMasterConfig) != HAL_OK)
  {
    Error_Handler();
  }

}

static void MX_TIM15_Init(void)
{

  TIM_ClockConfigTypeDef sClockSourceConfig = {0};
  TIM_MasterConfigTypeDef sMasterConfig = {0};

  htim15.Instance = TIM15;
  htim15.Init.Prescaler = 1000-1;
  htim15.Init.CounterMode = TIM_COUNTERMODE_UP;
  htim15.Init.Period = 169;
  htim15.Init.ClockDivision = TIM_CLOCKDIVISION_DIV1;
  htim15.Init.RepetitionCounter = 0;
  htim15.Init.AutoReloadPreload = TIM_AUTORELOAD_PRELOAD_ENABLE;
  if (HAL_TIM_Base_Init(&htim15) != HAL_OK)
  {
    Error_Handler();
  }
  sClockSourceConfig.ClockSource = TIM_CLOCKSOURCE_INTERNAL;
  if (HAL_TIM_ConfigClockSource(&htim15, &sClockSourceConfig) != HAL_OK)
  {
    Error_Handler();
  }
  sMasterConfig.MasterOutputTrigger = TIM_TRGO_UPDATE;
  sMasterConfig.MasterSlaveMode = TIM_MASTERSLAVEMODE_DISABLE;
  if (HAL_TIMEx_MasterConfigSynchronization(&htim15, &sMasterConfig) != HAL_OK)
  {
    Error_Handler();
  }

}

static void MX_USART3_UART_Init(void)
{

  huart3.Instance = USART3;
  huart3.Init.BaudRate = 31250;
  huart3.Init.WordLength = UART_WORDLENGTH_8B;
  huart3.Init.StopBits = UART_STOPBITS_1;
  huart3.Init.Parity = UART_PARITY_NONE;
  huart3.Init.Mode = UART_MODE_TX_RX;
  huart3.Init.HwFlowCtl = UART_HWCONTROL_NONE;
  huart3.Init.OverSampling = UART_OVERSAMPLING_16;
  huart3.Init.OneBitSampling = UART_ONE_BIT_SAMPLE_DISABLE;
  huart3.Init.ClockPrescaler = UART_PRESCALER_DIV1;
  huart3.AdvancedInit.AdvFeatureInit = UART_ADVFEATURE_NO_INIT;
  if (HAL_UART_Init(&huart3) != HAL_OK)
  {
    Error_Handler();
  }
  if (HAL_UARTEx_SetTxFifoThreshold(&huart3, UART_TXFIFO_THRESHOLD_1_8) != HAL_OK)
  {
    Error_Handler();
  }
  if (HAL_UARTEx_SetRxFifoThreshold(&huart3, UART_RXFIFO_THRESHOLD_1_8) != HAL_OK)
  {
    Error_Handler();
  }
  if (HAL_UARTEx_DisableFifoMode(&huart3) != HAL_OK)
  {
    Error_Handler();
  }

}

static void MX_DMA_Init(void)
{

  /* DMA controller clock enable */
  __HAL_RCC_DMAMUX1_CLK_ENABLE();
  __HAL_RCC_DMA1_CLK_ENABLE();

  /* DMA interrupt init */
  /* DMA1_Channel1_IRQn interrupt configuration */
  HAL_NVIC_SetPriority(DMA1_Channel1_IRQn, 0, 0);
  HAL_NVIC_EnableIRQ(DMA1_Channel1_IRQn);
  /* DMA1_Channel2_IRQn interrupt configuration */
  HAL_NVIC_SetPriority(DMA1_Channel2_IRQn, 0, 0);
  HAL_NVIC_EnableIRQ(DMA1_Channel2_IRQn);
  /* DMA1_Channel3_IRQn interrupt configuration */
  HAL_NVIC_SetPriority(DMA1_Channel3_IRQn, 0, 0);
  HAL_NVIC_EnableIRQ(DMA1_Channel3_IRQn);
  /* DMA1_Channel4_IRQn interrupt configuration */
  HAL_NVIC_SetPriority(DMA1_Channel4_IRQn, 10, 0);
  HAL_NVIC_EnableIRQ(DMA1_Channel4_IRQn);
  /* DMA1_Channel5_IRQn interrupt configuration */
  HAL_NVIC_SetPriority(DMA1_Channel5_IRQn, 0, 0);
  HAL_NVIC_EnableIRQ(DMA1_Channel5_IRQn);
  /* DMA1_Channel6_IRQn interrupt configuration */
  HAL_NVIC_SetPriority(DMA1_Channel6_IRQn, 0, 0);
  HAL_NVIC_EnableIRQ(DMA1_Channel6_IRQn);

}

static void MX_GPIO_Init(void)
{
  GPIO_InitTypeDef GPIO_InitStruct = {0};

  /* GPIO Ports Clock Enable */
  __HAL_RCC_GPIOC_CLK_ENABLE();
  __HAL_RCC_GPIOF_CLK_ENABLE();
  __HAL_RCC_GPIOA_CLK_ENABLE();
  __HAL_RCC_GPIOB_CLK_ENABLE();

  /*Configure GPIO pin Output Level */
  HAL_GPIO_WritePin(LED_BUILTIN_GPIO_Port, LED_BUILTIN_Pin, GPIO_PIN_RESET);

  /*Configure GPIO pin Output Level */
  HAL_GPIO_WritePin(LATCH_GPIO_Port, LATCH_Pin, GPIO_PIN_RESET);

  /*Configure GPIO pin : PUSH6_Pin */
  GPIO_InitStruct.Pin = PUSH6_Pin;
  GPIO_InitStruct.Mode = GPIO_MODE_INPUT;
  GPIO_InitStruct.Pull = GPIO_PULLUP;
  HAL_GPIO_Init(PUSH6_GPIO_Port, &GPIO_InitStruct);

  /*Configure GPIO pin : LED_BUILTIN_Pin */
  GPIO_InitStruct.Pin = LED_BUILTIN_Pin;
  GPIO_InitStruct.Mode = GPIO_MODE_OUTPUT_PP;
  GPIO_InitStruct.Pull = GPIO_NOPULL;
  GPIO_InitStruct.Speed = GPIO_SPEED_FREQ_LOW;
  HAL_GPIO_Init(LED_BUILTIN_GPIO_Port, &GPIO_InitStruct);

  /*Configure GPIO pin : LATCH_Pin */
  GPIO_InitStruct.Pin = LATCH_Pin;
  GPIO_InitStruct.Mode = GPIO_MODE_OUTPUT_PP;
  GPIO_InitStruct.Pull = GPIO_NOPULL;
  GPIO_InitStruct.Speed = GPIO_SPEED_FREQ_LOW;
  HAL_GPIO_Init(LATCH_GPIO_Port, &GPIO_InitStruct);

  /*Configure GPIO pins : SOFT_POWER_Pin PUSH1_Pin PUSH2_Pin PUSH3_Pin
                           PUSH4_Pin PUSH5_Pin */
  GPIO_InitStruct.Pin = SOFT_POWER_Pin|PUSH1_Pin|PUSH2_Pin|PUSH3_Pin
                          |PUSH4_Pin|PUSH5_Pin;
  GPIO_InitStruct.Mode = GPIO_MODE_INPUT;
  GPIO_InitStruct.Pull = GPIO_PULLUP;
  HAL_GPIO_Init(GPIOB, &GPIO_InitStruct);

}

void Error_Handler(void)
{
	__disable_irq();
	while (1) {
	}
}
